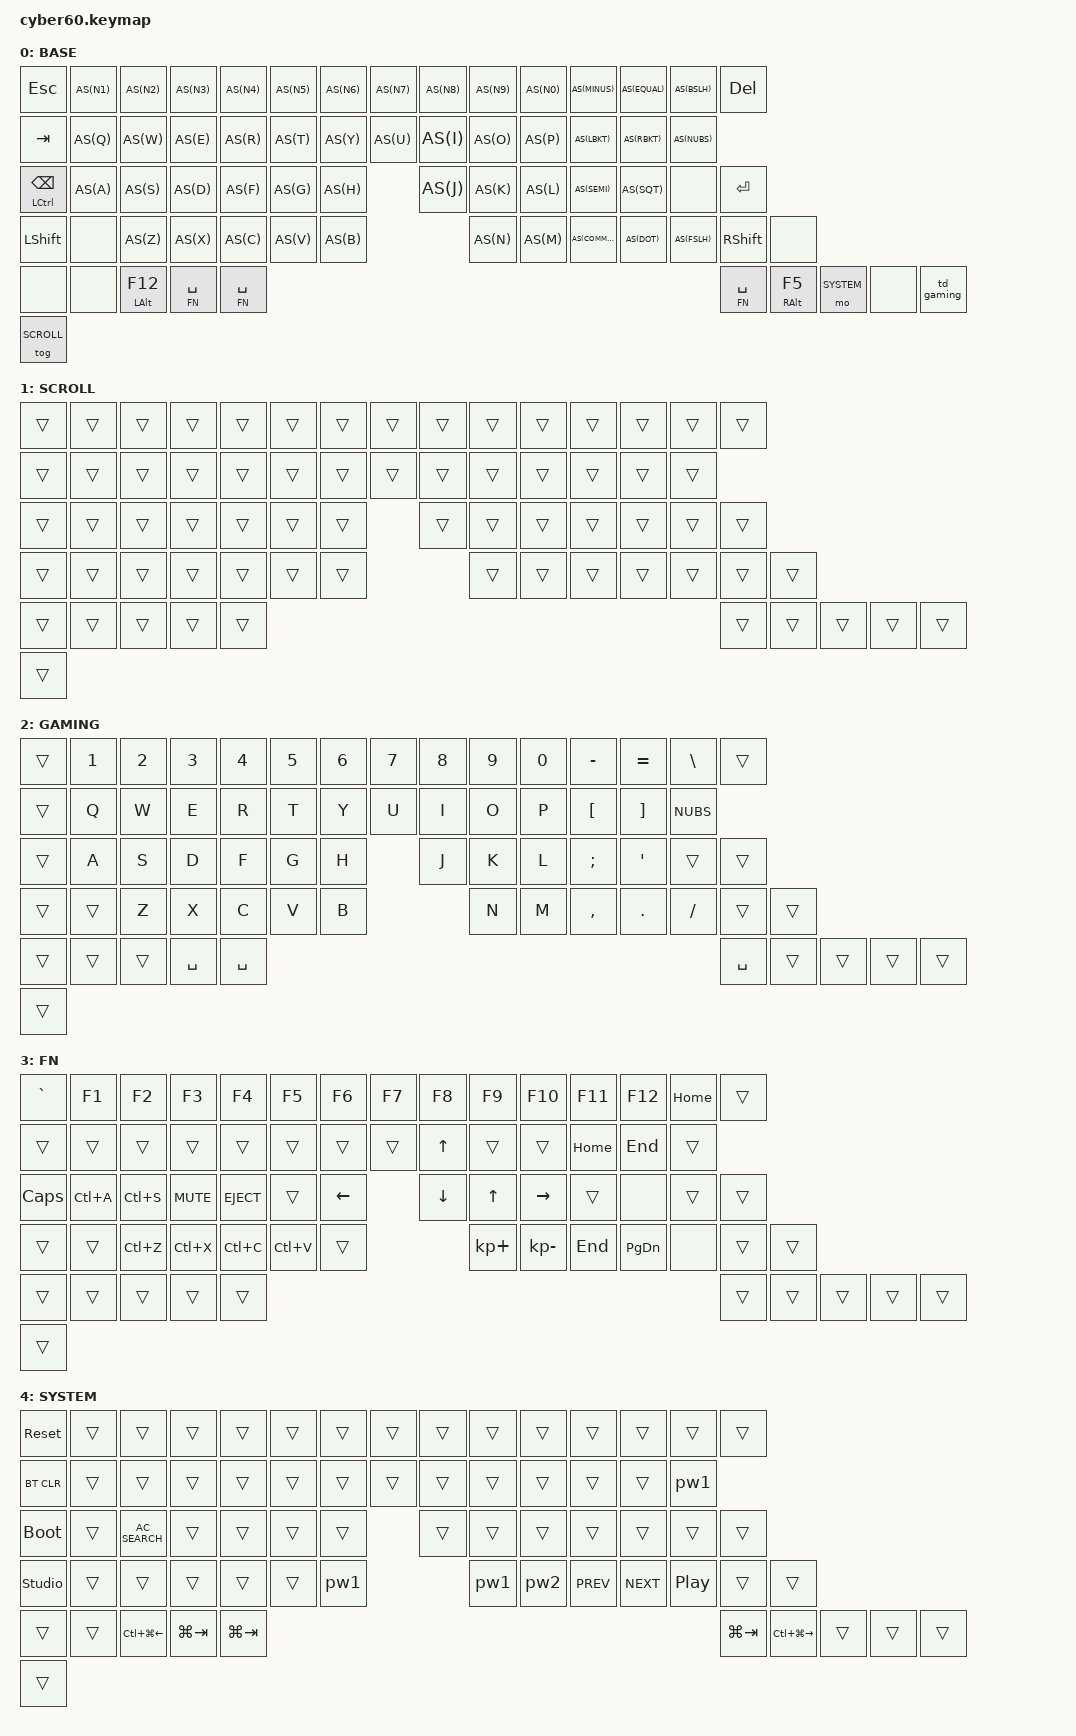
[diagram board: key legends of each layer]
/*
 * Cyber60 keymap, the one and only. Today it runs on the Prospector dongle
 * (prospector_dongle.keymap includes this file): the keyboard is the split
 * peripheral and only reports key positions. The Pi desk screen variant
 * (tools/build.sh keyboard-pi, parked since 2026-11-05) builds this same file
 * into a standalone keyboard instead. Edit the keymap here only.
 *
 * Base layer copied from the Rama M60-A (work keyboard) so muscle memory
 * carries over, plus auto shift and a GAMING layer. The top-right corner is a
 * Del switch since 2026-11-06 (the rotary encoder that sat there came out).
 *
 * Layer order matters:
 *   - GAMING sits above SCROLL so combos stay off while gaming (combos check
 *     the top layer) and the screen shows GAMING.
 *   - FN and SYSTEM sit above GAMING so holding them still works while gaming.
 *   - Only BASE and SCROLL have sensor-bindings; the encoder falls through the
 *     other layers to whichever of those is on top. With no encoder fitted
 *     they (and SCROLL) are idle, but kept: the layer numbers stay put, and
 *     putting the encoder back needs no firmware change.
 * The screen/underglow colours are indexed by this order
 * (boards/shields/prospector_screen/src/layouts/operator/display_colors.h).
 *
 * Unknown/undecided keys are &none with a TODO.
 */

#include <behaviors.dtsi>
#include <dt-bindings/zmk/bt.h>
#include <dt-bindings/zmk/keys.h>
#include <dt-bindings/zmk/pointing.h>
#include <layer_glow.dtsi>

#define BASE    0
#define SCROLL  1
#define GAMING  2
#define FN      3
#define SYSTEM  4

#include "behaviors.dtsi"
#include "combos.dtsi"

// Password macros &pw1 / &pw2. The real ones are gitignored and only exist on
// the build box; everywhere else the placeholders (type nothing) are used.
#if __has_include("secrets/passwords.dtsi")
#include "secrets/passwords.dtsi"
#else
#include "secrets/passwords.example.dtsi"
#endif

/ {
    keymap {
        compatible = "zmk,keymap";

        base_layer {
            display-name = "BASE";
/*  ┌────┬────┬────┬────┬────┬────┬────┬────┬────┬────┬────┬────┬────┬────┬────┐
    │Esc │ 1  │ 2  │ 3  │ 4  │ 5  │ 6  │ 7  │ 8  │ 9  │ 0  │ -  │ =  │ \  │Del │
    ├────┴──┬─┴──┬─┴──┬─┴──┬─┴──┬─┴──┬─┴──┬─┴──┬─┴──┬─┴──┬─┴──┬─┴──┬─┴──┬─┴────┤
    │ Tab   │ Q  │ W  │ E  │ R  │ T  │ Y  │ U  │ I  │ O  │ P  │ [  │ ]  │ <>|  │
    ├───────┴┬───┴┬───┴┬───┴┬───┴┬───┴┬───┴┬───┴┬───┴┬───┴┬───┴┬───┴┬───┴──────┤
    │Ctrl/Bsp│ A  │ S  │ D  │ F  │ G  │ H  │ J  │ K  │ L  │ ;  │ '  │  Enter   │
    ├────────┴──┬─┴──┬─┴──┬─┴──┬─┴──┬─┴──┬─┴──┬─┴──┬─┴──┬─┴──┬─┴──┬─┴──────┬──┤
    │  LShift   │ Z  │ X  │ C  │ V  │ B  │ N  │ M  │ ,  │ .  │ /  │ RShift │ ?│
    ├─────┬─────┼────┴┬───┴────┴────┴────┴────┴────┴──┬─┴───┬┴────┼─────┬──┴──┤
    │  ?  │  ?  │Alt  │         Space / FN            │AltGr│ SYS │  ?  │ ?/G │
    │     │     │/F12 │                               │/F5  │     │     │x2   │
    └─────┴─────┴─────┴───────────────────────────────┴─────┴─────┴─────┴─────┘
    All letters, digits and symbols auto-shift (hold = shifted).
    ?/G x2: double-tap toggles GAMING; single tap undecided.
    Del is a switch where the encoder was (2026-11-06). The encoder and Del share
    that spot on the board, so whichever is fitted works: Del is position 14,
    the encoder's push 67 (turn = volume, press = SCROLL mode on/off).          */
            bindings = <
&kp ESC        AS(N1) AS(N2) AS(N3) AS(N4) AS(N5) AS(N6) AS(N7) AS(N8) AS(N9) AS(N0) AS(MINUS) AS(EQUAL) AS(BSLH) &kp DEL
&kp TAB        AS(Q)  AS(W)  AS(E)  AS(R)  AS(T)  AS(Y)  AS(U)  AS(I)  AS(O)  AS(P)  AS(LBKT)  AS(RBKT)  AS(NUBS)
&mt LCTRL BSPC AS(A)  AS(S)  AS(D)  AS(F)  AS(G)  AS(H)  AS(J)  AS(K)  AS(L)  AS(SEMI) AS(SQT) &none /* ISO # */ &kp RET
&kp LSHFT      &none /* ISO <> */ AS(Z) AS(X) AS(C) AS(V) AS(B) AS(N) AS(M) AS(COMMA) AS(DOT) AS(FSLH) &kp RSHFT &none /* TODO: M60-A TG(2), layer dropped */
&none /* TODO */ &none /* TODO: M60-A 0x5702 */ &mt LALT F12   &lt FN SPACE &lt FN SPACE &lt FN SPACE   &mt RALT F5 &mo SYSTEM &none /* TODO */ &td_gaming
&tog SCROLL
            >;
            sensor-bindings = <&inc_dec_kp C_VOL_UP C_VOL_DN>;
        };

        scroll_layer {
            display-name = "SCROLL";
/*  Toggled by pressing the encoder. Every key is transparent; only the encoder
    changes: turning it scrolls (mouse wheel) instead of changing volume.
    Unreachable while no encoder is fitted (since 2026-11-06).                 */
            bindings = <
&trans &trans &trans &trans &trans &trans &trans &trans &trans &trans &trans &trans &trans &trans &trans
&trans &trans &trans &trans &trans &trans &trans &trans &trans &trans &trans &trans &trans &trans
&trans &trans &trans &trans &trans &trans &trans &trans &trans &trans &trans &trans &trans &trans
&trans &trans &trans &trans &trans &trans &trans &trans &trans &trans &trans &trans &trans &trans
&trans &trans &trans &trans &trans &trans &trans &trans &trans &trans
&trans
            >;
            sensor-bindings = <&enc_scroll>;
        };

        gaming_layer {
            display-name = "GAMING";
/*  Double-tap the bottom-right corner key to enter/leave. Plain keys where
    BASE has auto shift, and a plain Space (so holding Space to jump works;
    FN is then not reachable while gaming). No combos fire on this layer.
    Everything else falls through to BASE.                                      */
            bindings = <
&trans &kp N1 &kp N2 &kp N3 &kp N4 &kp N5 &kp N6 &kp N7 &kp N8 &kp N9 &kp N0 &kp MINUS &kp EQUAL &kp BSLH &trans
&trans &kp Q  &kp W  &kp E  &kp R  &kp T  &kp Y  &kp U  &kp I  &kp O  &kp P  &kp LBKT  &kp RBKT  &kp NUBS
&trans &kp A  &kp S  &kp D  &kp F  &kp G  &kp H  &kp J  &kp K  &kp L  &kp SEMI &kp SQT &trans &trans
&trans &trans &kp Z  &kp X  &kp C  &kp V  &kp B  &kp N  &kp M  &kp COMMA &kp DOT &kp FSLH &trans &trans
&trans &trans &trans &kp SPACE &kp SPACE &kp SPACE &trans &trans &trans &trans
&trans
            >;
        };

        fn_layer {
            display-name = "FN";
/*  Hold Space. Copied from the M60-A's Fn1.
    ┌────┬────┬────┬────┬────┬────┬────┬────┬────┬────┬────┬────┬────┬────┬────┐
    │ `  │ F1 │ F2 │ F3 │ F4 │ F5 │ F6 │ F7 │ F8 │ F9 │F10 │F11 │F12 │Home│    │
    ├────┴──┬─┴──┬─┴──┬─┴──┬─┴──┬─┴──┬─┴──┬─┴──┬─┴──┬─┴──┬─┴──┬─┴──┬─┴──┬─┴────┤
    │       │    │    │    │    │    │    │    │ Up │    │    │Home│End │      │
    ├───────┴┬───┴┬───┴┬───┴┬───┴┬───┴┬───┴┬───┴┬───┴┬───┴┬───┴┬───┴┬───┴──────┤
    │CapsLock│^A  │^S  │Mute│Ejct│    │ ←  │ ↓  │ ↑  │ →  │    │ ✕  │          │
    ├────────┴──┬─┴──┬─┴──┬─┴──┬─┴──┬─┴──┬─┴──┬─┴──┬─┴──┬─┴──┬─┴──┬─┴──────┬──┤
    │           │^Z  │^X  │^C  │^V  │    │KP+ │KP- │End │PgDn│ ?  │        │  │
    └───────────┴────┴────┴────┴────┴────┴────┴────┴────┴────┴────┴────────┴──┘
    ✕ = KC_NO on the M60-A.  ? = TODO: M60-A's 0x5701 (unknown).               */
            bindings = <
&kp GRAVE &kp F1 &kp F2 &kp F3 &kp F4 &kp F5 &kp F6 &kp F7 &kp F8 &kp F9 &kp F10 &kp F11 &kp F12 &kp HOME &trans
&trans &trans &trans &trans &trans &trans &trans &trans &kp UP &trans &trans &kp HOME &kp END &trans
&kp CAPS &kp LC(A) &kp LC(S) &kp C_MUTE &kp C_EJECT &trans &kp LEFT &kp DOWN &kp UP &kp RIGHT &trans &none &trans &trans
&trans &trans &kp LC(Z) &kp LC(X) &kp LC(C) &kp LC(V) &trans &kp KP_PLUS &kp KP_MINUS &kp END &kp PG_DN &none /* TODO: M60-A 0x5701 */ &trans &trans
&trans &trans &trans &trans &trans &trans &trans &trans &trans &trans
&trans
            >;
        };

        system_layer {
            display-name = "SYSTEM";
/*  Hold SYS. Copied from the M60-A's layer 3, plus keyboard maintenance keys.
    ┌─────┬────┬────┬────┬────┬────┬────┬────┬────┬────┬────┬────┬────┬────┬────┐
    │Reset│    │    │    │    │    │    │    │    │    │    │    │    │    │    │
    ├─────┴─┬──┴─┬──┴─┬──┴─┬──┴─┬──┴─┬──┴─┬──┴─┬──┴─┬──┴─┬──┴─┬──┴─┬──┴─┬──┴────┤
    │BT clr │    │    │    │    │    │    │    │    │    │    │    │    │ PW1   │
    ├───────┴┬───┴┬───┴┬───┴┬───┴┬───┴┬───┴┬───┴┬───┴┬───┴┬───┴┬───┴┬───┴───────┤
    │ Flash  │    │Srch│    │    │    │    │    │    │    │    │    │           │
    ├────────┴──┬─┴──┬─┴──┬─┴──┬─┴──┬─┴──┬─┴──┬─┴──┬─┴──┬─┴──┬─┴──┬─┴──────┬───┤
    │ Studio    │    │    │    │    │PW1 │PW1 │PW2 │Prev│Next│Play│        │   │
    ├─────┬─────┼────┴┬───┴────┴────┴────┴────┴────┴──┬─┴───┬┴────┼─────┬──┴───┤
    │     │     │Desk←│           Win+Tab             │Desk→│     │     │      │
    └─────┴─────┴─────┴───────────────────────────────┴─────┴─────┴─────┴──────┘
    Reset restarts the keyboard, Flash puts it in bootloader mode (a USB drive
    appears; drop the keyboard .uf2 on it, or tools/flash.sh does it through
    the Pi). Both act on the keyboard itself, also with the dongle. BT clr
    forgets the Bluetooth host on the current profile: with the dongle, the
    dongle's own host (when it runs on Bluetooth instead of USB); standalone,
    the Pi (profile 1).
    D + F together (combo) = put the DONGLE in bootloader mode, to flash it in
    place (combos.dtsi: a reset fired by a combo runs on the dongle).
    Studio = unlock ZMK Studio for editing.  Desk←/→ = Ctrl+Win+←/→.
    PW1/PW2 = password macros &pw1 (Swedish layout) / &pw2 (English layout),
    on the same keys as the M60-A's layer 3 (<>|, B, N = PW1; M = PW2).        */
            bindings = <
&sys_reset &trans &trans &trans &trans &trans &trans &trans &trans &trans &trans &trans &trans &trans &trans
&bt BT_CLR &trans &trans &trans &trans &trans &trans &trans &trans &trans &trans &trans &trans &pw1
&bootloader &trans &kp C_AC_SEARCH &trans &trans &trans &trans &trans &trans &trans &trans &trans &trans &trans
&studio_unlock &trans &trans &trans &trans &trans &pw1 &pw1 &pw2 &kp C_PREV &kp C_NEXT &kp C_PP &trans &trans
&trans &trans &kp LC(LG(LEFT)) &kp LG(TAB) &kp LG(TAB) &kp LG(TAB) &kp LC(LG(RIGHT)) &trans &trans &trans
&trans
            >;
        };
    };
};
